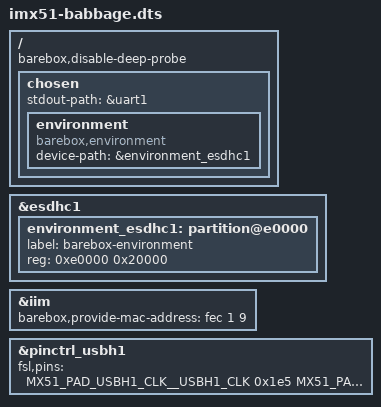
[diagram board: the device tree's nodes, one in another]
/*
 * Copyright 2011 Freescale Semiconductor, Inc.
 * Copyright 2011 Linaro Ltd.
 *
 * The code contained herein is licensed under the GNU General Public
 * License. You may obtain a copy of the GNU General Public License
 * Version 2 or later at the following locations:
 *
 * http://www.opensource.org/licenses/gpl-license.html
 * http://www.gnu.org/copyleft/gpl.html
 */

#include <arm/nxp/imx/imx51-babbage.dts>

/ {
	barebox,disable-deep-probe;

	chosen {
		stdout-path = &uart1;

		environment {
			compatible = "barebox,environment";
			device-path = &environment_esdhc1;
		};
	};
};

&esdhc1 {
	#address-cells = <1>;
	#size-cells = <1>;

	environment_esdhc1: partition@e0000 {
		label = "barebox-environment";
		reg = <0xe0000 0x20000>;
	};
};

&iim {
	barebox,provide-mac-address = <&fec 1 9>;
};

&pinctrl_usbh1 {
	fsl,pins = <
		MX51_PAD_USBH1_CLK__USBH1_CLK		0x1e5
		MX51_PAD_USBH1_DIR__USBH1_DIR		0x1e5
	        MX51_PAD_USBH1_NXT__USBH1_NXT		0x1e5
		MX51_PAD_USBH1_STP__USBH1_STP		0x1e5
		MX51_PAD_USBH1_DATA0__USBH1_DATA0	0x1e5
		MX51_PAD_USBH1_DATA1__USBH1_DATA1	0x1e5
		MX51_PAD_USBH1_DATA2__USBH1_DATA2	0x1e5
		MX51_PAD_USBH1_DATA3__USBH1_DATA3	0x1e5
		MX51_PAD_USBH1_DATA4__USBH1_DATA4	0x1e5
		MX51_PAD_USBH1_DATA5__USBH1_DATA5	0x1e5
		MX51_PAD_USBH1_DATA6__USBH1_DATA6	0x1e5
		MX51_PAD_USBH1_DATA7__USBH1_DATA7	0x1e5
	>;
};
